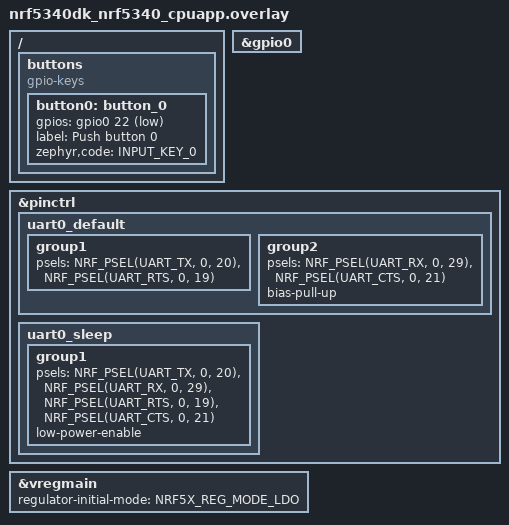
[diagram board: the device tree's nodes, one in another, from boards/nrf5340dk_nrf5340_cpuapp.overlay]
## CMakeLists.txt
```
#
# Copyright (c) 2024 Nordic Semiconductor ASA
#
# SPDX-License-Identifier: LicenseRef-Nordic-5-Clause
#

cmake_minimum_required(VERSION 3.20.0)

find_package(Zephyr REQUIRED HINTS $ENV{ZEPHYR_BASE})

project(gpio_idle)

target_sources(app PRIVATE src/main.c)
```

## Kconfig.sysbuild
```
#
# Copyright (c) 2025 Nordic Semiconductor ASA
#
# SPDX-License-Identifier: LicenseRef-Nordic-5-Clause
#

if SOC_NRF54H20_CPUAPP

choice NETCORE
	default NETCORE_EMPTY

endchoice

endif

source "share/sysbuild/Kconfig"
```

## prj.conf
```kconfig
CONFIG_GPIO=y
CONFIG_CONSOLE=n
CONFIG_UART_CONSOLE=n
CONFIG_SERIAL=n
CONFIG_POWEROFF=y
CONFIG_PRINTK=y
```

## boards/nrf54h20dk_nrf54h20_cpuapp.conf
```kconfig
CONFIG_SOC_NRF54H20_CPURAD_ENABLE=y
CONFIG_PM=y
```

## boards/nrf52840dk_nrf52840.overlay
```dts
/*
 * Copyright (c) 2025 Nordic Semiconductor ASA
 *
 * SPDX-License-Identifier: LicenseRef-Nordic-5-Clause
 */

/ {
	/*
	 * Redefine sw0/button0 to use RXD1 - P0.08
	 * Thus, when sending character from host, there will be gpio interrupt,
	 * the same as originally triggered by sw0 button.
	 */
	buttons {
		compatible = "gpio-keys";

		button0: button_0 {
			gpios = <&gpio0 8 (GPIO_PULL_UP | GPIO_ACTIVE_LOW)>;
			label = "Push button 0";
			zephyr,code = <INPUT_KEY_0>;
		};
	};
};

&gpio0 {
	status = "okay";
};

/*
 * Redefine RX -> P0.04 (not used)
 */
&pinctrl {
	uart0_default: uart0_default {
		group1 {
			psels = <NRF_PSEL(UART_TX, 0, 6)>,
				<NRF_PSEL(UART_RTS, 0, 5)>;
		};

		group2 {
			psels = <NRF_PSEL(UART_RX, 0, 4)>,
				<NRF_PSEL(UART_CTS, 0, 7)>;
			bias-pull-up;
		};
	};

	uart0_sleep: uart0_sleep {
		group1 {
			psels = <NRF_PSEL(UART_TX, 0, 6)>,
				<NRF_PSEL(UART_RX, 0, 4)>,
				<NRF_PSEL(UART_RTS, 0, 5)>,
				<NRF_PSEL(UART_CTS, 0, 7)>;
			low-power-enable;
		};
	};
};
```

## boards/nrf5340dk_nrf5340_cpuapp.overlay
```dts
/*
 * Copyright (c) 2025 Nordic Semiconductor ASA
 *
 * SPDX-License-Identifier: LicenseRef-Nordic-5-Clause
 */

/ {
	/*
	 * Redefine sw0/button0 to use RXD1 - P0.22
	 * Thus, when sending character from host, there will be gpio interrupt,
	 * the same as originally triggered by sw0 button.
	 */
	buttons {
		compatible = "gpio-keys";

		button0: button_0 {
			gpios = <&gpio0 22 (GPIO_PULL_UP | GPIO_ACTIVE_LOW)>;
			label = "Push button 0";
			zephyr,code = <INPUT_KEY_0>;
		};
	};
};

&gpio0 {
	status = "okay";
};

/*
 * Redefine RX -> P0.29 (not used)
 */
&pinctrl {
	uart0_default: uart0_default {
		group1 {
			psels = <NRF_PSEL(UART_TX, 0, 20)>,
				<NRF_PSEL(UART_RTS, 0, 19)>;
		};

		group2 {
			psels = <NRF_PSEL(UART_RX, 0, 29)>,
				<NRF_PSEL(UART_CTS, 0, 21)>;
			bias-pull-up;
		};
	};

	uart0_sleep: uart0_sleep {
		group1 {
			psels = <NRF_PSEL(UART_TX, 0, 20)>,
				<NRF_PSEL(UART_RX, 0, 29)>,
				<NRF_PSEL(UART_RTS, 0, 19)>,
				<NRF_PSEL(UART_CTS, 0, 21)>;
			low-power-enable;
		};
	};
};

&vregmain {
	regulator-initial-mode = <NRF5X_REG_MODE_LDO>;
};
```

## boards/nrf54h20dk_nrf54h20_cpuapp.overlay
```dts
/*
 * Copyright (c) 2025 Nordic Semiconductor ASA
 *
 * SPDX-License-Identifier: LicenseRef-Nordic-5-Clause
 */

/ {
	/*
	 * Redefine sw0/button0 to use RXD0 - P2.04
	 * Thus, when sending character from host, there will be gpio interrupt,
	 * the same as originally triggered by sw0 button.
	 */
	buttons {
		compatible = "gpio-keys";

		button0: button_0 {
			gpios = <&gpio2 4 (GPIO_PULL_UP | GPIO_ACTIVE_LOW)>;
			label = "Push button 0";
			zephyr,code = <INPUT_KEY_0>;
		};
	};
};

&gpio2 {
	status = "okay";
};
```

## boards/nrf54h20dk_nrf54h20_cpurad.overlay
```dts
/*
 * Copyright (c) 2025 Nordic Semiconductor ASA
 *
 * SPDX-License-Identifier: LicenseRef-Nordic-5-Clause
 */

/ {
	aliases {
		sw0 = &button0;
	};

	/*
	 * Redefine sw0/button0 to use RXD1 - P1.10
	 * Thus, when sending character from host, there will be gpio interrupt,
	 * the same as originally triggered by sw0 button.
	 */
	buttons {
		compatible = "gpio-keys";

		button0: button_0 {
			gpios = <&gpio2 4 (GPIO_PULL_UP | GPIO_ACTIVE_LOW)>;
			label = "Push button 0";
			zephyr,code = <INPUT_KEY_0>;
		};
	};
};

&gpiote130 {
	status = "okay";
};

&gpio2 {
	status = "okay";
};
```

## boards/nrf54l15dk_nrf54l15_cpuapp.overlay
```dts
/*
 * Copyright (c) 2024 Nordic Semiconductor ASA
 *
 * SPDX-License-Identifier: LicenseRef-Nordic-5-Clause
 */

/ {
	/*
	 * Redefine sw0/button0 to use RXD1 - P1.05
	 * Thus, when sending character from host, there will be gpio interrupt,
	 * the same as originally triggered by sw0 button.
	 */
	buttons {
		compatible = "gpio-keys";

		button0: button_0 {
			gpios = <&gpio1 5 (GPIO_PULL_UP | GPIO_ACTIVE_LOW)>;
			label = "Push button 0";
			zephyr,code = <INPUT_KEY_0>;
		};
	};
};

&gpio1 {
	status = "okay";
};

/*
 * Redefine RX -> P1.03 (not used)
 */
&pinctrl {
	/omit-if-no-ref/ uart20_default: uart20_default {
		group1 {
			psels = <NRF_PSEL(UART_TX, 1, 4)>,
				<NRF_PSEL(UART_RTS, 1, 6)>;
		};

		group2 {
			psels = <NRF_PSEL(UART_RX, 1, 3)>,
				<NRF_PSEL(UART_CTS, 1, 7)>;
			bias-pull-up;
		};
	};

	/omit-if-no-ref/ uart20_sleep: uart20_sleep {
		group1 {
			psels = <NRF_PSEL(UART_TX, 1, 4)>,
				<NRF_PSEL(UART_RX, 1, 3)>,
				<NRF_PSEL(UART_RTS, 1, 6)>,
				<NRF_PSEL(UART_CTS, 1, 7)>;
			low-power-enable;
		};
	};
};
```

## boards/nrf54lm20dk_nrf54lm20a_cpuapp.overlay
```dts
/ {
	/*
	 * Redefine sw0/button0 to use RXD1 - P1.17
	 * Thus, when sending character from host, there will be gpio interrupt,
	 * the same as originally triggered by sw0 button.
	 */
	buttons {
		compatible = "gpio-keys";

		button0: button_0 {
			gpios = <&gpio1 17 (GPIO_PULL_UP | GPIO_ACTIVE_LOW)>;
			label = "Input 0";
			zephyr,code = <INPUT_KEY_0>;
		};
	};
};

&pinctrl {
	/*
	 * Redefine: RXD1 -> P1.13 (any other valid pin)
	 */
	/omit-if-no-ref/ uart20_default: uart20_default {
		group1 {
			psels = <NRF_PSEL(UART_TX, 1, 16)>,
				<NRF_PSEL(UART_RTS, 1, 18)>;
		};

		group2 {
			psels = <NRF_PSEL(UART_RX, 1, 13)>,
				<NRF_PSEL(UART_CTS, 1, 19)>;
			bias-pull-up;
		};
	};

	/omit-if-no-ref/ uart20_sleep: uart20_sleep {
		group1 {
			psels = <NRF_PSEL(UART_TX, 1, 16)>,
				<NRF_PSEL(UART_RX, 1, 13)>,
				<NRF_PSEL(UART_RTS, 1, 18)>,
				<NRF_PSEL(UART_CTS, 1, 19)>;
			low-power-enable;
		};
	};
};
```

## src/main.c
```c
/*
 * Copyright (c) 2024 Nordic Semiconductor ASA
 *
 * SPDX-License-Identifier: LicenseRef-Nordic-5-Clause
 */

#include <zephyr/kernel.h>
#include <zephyr/drivers/gpio.h>

static const struct gpio_dt_spec sw = GPIO_DT_SPEC_GET(DT_ALIAS(sw0), gpios);

static K_SEM_DEFINE(my_gpio_sem, 0, 1);

void my_gpio_callback(const struct device *dev, struct gpio_callback *cb, uint32_t pins)
{
	k_sem_give(&my_gpio_sem);
}

static struct gpio_callback gpio_cb;

int main(void)
{
	int ret;

	ret = gpio_is_ready_dt(&sw);
	if (ret < 0) {
		printk("GPIO Device not ready (%d)\n", ret);
		return 0;
	}

	ret = gpio_pin_configure_dt(&sw, GPIO_INPUT);
	if (ret < 0) {
		printk("Could not configure sw GPIO (%d)\n", ret);
		return 0;
	}

	ret = gpio_pin_interrupt_configure(sw.port, sw.pin, GPIO_INT_LEVEL_ACTIVE);
	if (ret < 0) {
		printk("Could not configure sw GPIO interrupt (%d)\n", ret);
		return 0;
	}
	gpio_init_callback(&gpio_cb, my_gpio_callback, BIT(sw.pin));
	gpio_add_callback(sw.port, &gpio_cb);

	while (1) {
		if (k_sem_take(&my_gpio_sem, K_FOREVER) != 0) {
			printk("Failed to take a semaphore\n");
			return 0;
		}
		k_busy_wait(1000000);
		k_sem_reset(&my_gpio_sem);
	}

	return 0;
}
```
